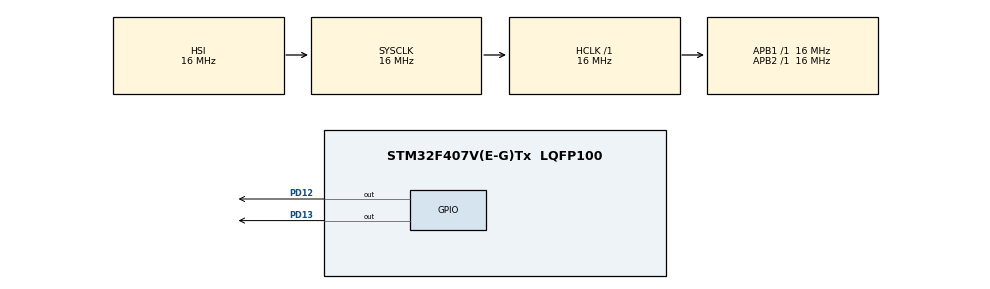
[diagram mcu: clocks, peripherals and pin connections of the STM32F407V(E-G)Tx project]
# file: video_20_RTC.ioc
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Mcu.Family=STM32F4
Mcu.Name=STM32F407V(E-G)Tx
Mcu.Package=LQFP100
NVIC.PriorityGroup=NVIC_PRIORITYGROUP_4
NVIC.RTC_Alarm_IRQn=true\:0\:0\:false\:false\:true\:true
PA13.Mode=Serial_Wire
PA13.Signal=SYS_JTMS-SWDIO
PA14.Mode=Serial_Wire
PA14.Signal=SYS_JTCK-SWCLK
PD12.Signal=GPIO_Output
PD13.Signal=GPIO_Output
ProjectManager.HeapSize=0x200
ProjectManager.StackSize=0x400
ProjectManager.TargetToolchain=MDK-ARM V5
RCC.AHBFreq_Value=16000000
RCC.APB1Freq_Value=16000000
RCC.APB1TimFreq_Value=16000000
RCC.APB2Freq_Value=16000000
RCC.APB2TimFreq_Value=16000000
RCC.CortexFreq_Value=16000000
RCC.HCLKFreq_Value=16000000
RCC.HSE_VALUE=25000000
RCC.HSI_VALUE=16000000
RCC.SYSCLKFreq_VALUE=16000000
RCC.VCOOutputFreq_Value=192000000
RTC.Alarm=RTC_ALARM_A
RTC.AlarmDateWeekDaySel=RTC_ALARMDATEWEEKDAYSEL_DATE
RTC.Date=31
RTC.Format=RTC_FORMAT_BIN
RTC.Hours=23
RTC.Minutes=59
RTC.Month=RTC_MONTH_DECEMBER
RTC.Seconds=45
RTC.Seconds_A=10
RTC.Year=18
VP_RTC_VS_RTC_Activate.Mode=RTC_Enabled
VP_RTC_VS_RTC_Alarm_A_Intern.Mode=Alarm A
VP_RTC_VS_RTC_Calendar.Mode=RTC_Calendar
board=video_20_RTC

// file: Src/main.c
/**
  ******************************************************************************
  * File Name          : main.c
  * Description        : Main program body
  ******************************************************************************
  ** This notice applies to any and all portions of this file
  * that are not between comment pairs USER CODE BEGIN and
  * USER CODE END. Other portions of this file, whether
  * inserted by the user or by software development tools
  * are owned by their respective copyright owners.
  *
  * COPYRIGHT(c) 2018 STMicroelectronics
  *
  * Redistribution and use in source and binary forms, with or without modification,
  * are permitted provided that the following conditions are met:
  *   1. Redistributions of source code must retain the above copyright notice,
  *      this list of conditions and the following disclaimer.
  *   2. Redistributions in binary form must reproduce the above copyright notice,
  *      this list of conditions and the following disclaimer in the documentation
  *      and/or other materials provided with the distribution.
  *   3. Neither the name of STMicroelectronics nor the names of its contributors
  *      may be used to endorse or promote products derived from this software
  *      without specific prior written permission.
  *
  * THIS SOFTWARE IS PROVIDED BY THE COPYRIGHT HOLDERS AND CONTRIBUTORS "AS IS"
  * AND ANY EXPRESS OR IMPLIED WARRANTIES, INCLUDING, BUT NOT LIMITED TO, THE
  * IMPLIED WARRANTIES OF MERCHANTABILITY AND FITNESS FOR A PARTICULAR PURPOSE ARE
  * DISCLAIMED. IN NO EVENT SHALL THE COPYRIGHT HOLDER OR CONTRIBUTORS BE LIABLE
  * FOR ANY DIRECT, INDIRECT, INCIDENTAL, SPECIAL, EXEMPLARY, OR CONSEQUENTIAL
  * DAMAGES (INCLUDING, BUT NOT LIMITED TO, PROCUREMENT OF SUBSTITUTE GOODS OR
  * SERVICES; LOSS OF USE, DATA, OR PROFITS; OR BUSINESS INTERRUPTION) HOWEVER
  * CAUSED AND ON ANY THEORY OF LIABILITY, WHETHER IN CONTRACT, STRICT LIABILITY,
  * OR TORT (INCLUDING NEGLIGENCE OR OTHERWISE) ARISING IN ANY WAY OUT OF THE USE
  * OF THIS SOFTWARE, EVEN IF ADVISED OF THE POSSIBILITY OF SUCH DAMAGE.
  *
  ******************************************************************************
  */
#include "main.h"
#include "stm32f4xx_hal.h"

RTC_HandleTypeDef hrtc;
RTC_TimeTypeDef  sTime;             //<== tanimlama kismi
RTC_DateTypeDef  sDate;

/* USER CODE BEGIN PV */
/* Private variables ---------------------------------------------------------*/

/* USER CODE END PV */

void SystemClock_Config(void);
static void MX_GPIO_Init(void);
static void MX_RTC_Init(void);

/* USER CODE BEGIN PFP */
/* Private function prototypes -----------------------------------------------*/

/* USER CODE END PFP */

int main(void)
{

  /* MCU Configuration----------------------------------------------------------*/

  /* Reset of all peripherals, Initializes the Flash interface and the Systick. */
  HAL_Init();

  /* Configure the system clock */
  SystemClock_Config();

  /* Initialize all configured peripherals */
  MX_GPIO_Init();
  MX_RTC_Init();

//  videoda adamin yaptigi ama bnm yapmama gerek olmayan kisim :
// ilk yaptigimda bunlara gerek yoktu ama sonradan bu kodlari uncomment yapmak zorunda kaldim
// asagida fonksiyonda var ama bastan yükleyince degismedi dene acaba????
  /* USER CODE BEGIN 2 */
	// --------------------------------------------------------
//  // 1) Set time:
//    sTime.Hours = 23;
//    sTime.Minutes = 59;
//    sTime.Seconds = 45;
//	HAL_RTC_SetTime(&hrtc, &sTime, RTC_FORMAT_BIN);
//  // Sknti su nasil o fonksiyonun içinde deger atayacagim ??????????????
////	 ------------------------------------------------------------
//	// 2) Set date:
//	sDate.WeekDay = RTC_WEEKDAY_SUNDAY;
//  sDate.Month = RTC_MONTH_DECEMBER;
//  sDate.Date = 31;
//	sDate.Year = 18;
//	HAL_RTC_SetDate(&hrtc, &sDate, RTC_FORMAT_BIN);
//// ------------------------------------------------------------------ uncomment yaptigim yerin sonu
//  STM YI ÇIKARTIP SONRA PROGRAMI YÜKLEYINCE ÇALISIYOR  :|
  /* USER CODE END 2 */

  /* Infinite loop */
  while (1)
  {
	 HAL_RTC_GetTime(&hrtc,&sTime,RTC_FORMAT_BIN);
	 HAL_RTC_GetDate(&hrtc,&sDate,RTC_FORMAT_BIN);
   HAL_GPIO_TogglePin(GPIOD,GPIO_PIN_13);
   HAL_Delay(200);
  }

}

/** System Clock Configuration
*/
void SystemClock_Config(void)
{

  RCC_OscInitTypeDef RCC_OscInitStruct;
  RCC_ClkInitTypeDef RCC_ClkInitStruct;
  RCC_PeriphCLKInitTypeDef PeriphClkInitStruct;

    /**Configure the main internal regulator output voltage
    */
  __HAL_RCC_PWR_CLK_ENABLE();

  __HAL_PWR_VOLTAGESCALING_CONFIG(PWR_REGULATOR_VOLTAGE_SCALE1);

    /**Initializes the CPU, AHB and APB busses clocks
    */
  RCC_OscInitStruct.OscillatorType = RCC_OSCILLATORTYPE_HSI|RCC_OSCILLATORTYPE_LSI;
  RCC_OscInitStruct.HSIState = RCC_HSI_ON;
  RCC_OscInitStruct.HSICalibrationValue = 16;
  RCC_OscInitStruct.LSIState = RCC_LSI_ON;
  RCC_OscInitStruct.PLL.PLLState = RCC_PLL_NONE;
  if (HAL_RCC_OscConfig(&RCC_OscInitStruct) != HAL_OK)
  {
    _Error_Handler(__FILE__, __LINE__);
  }

    /**Initializes the CPU, AHB and APB busses clocks
    */
  RCC_ClkInitStruct.ClockType = RCC_CLOCKTYPE_HCLK|RCC_CLOCKTYPE_SYSCLK
                              |RCC_CLOCKTYPE_PCLK1|RCC_CLOCKTYPE_PCLK2;
  RCC_ClkInitStruct.SYSCLKSource = RCC_SYSCLKSOURCE_HSI;
  RCC_ClkInitStruct.AHBCLKDivider = RCC_SYSCLK_DIV1;
  RCC_ClkInitStruct.APB1CLKDivider = RCC_HCLK_DIV1;
  RCC_ClkInitStruct.APB2CLKDivider = RCC_HCLK_DIV1;

  if (HAL_RCC_ClockConfig(&RCC_ClkInitStruct, FLASH_LATENCY_0) != HAL_OK)
  {
    _Error_Handler(__FILE__, __LINE__);
  }

  PeriphClkInitStruct.PeriphClockSelection = RCC_PERIPHCLK_RTC;
  PeriphClkInitStruct.RTCClockSelection = RCC_RTCCLKSOURCE_LSI;
  if (HAL_RCCEx_PeriphCLKConfig(&PeriphClkInitStruct) != HAL_OK)
  {
    _Error_Handler(__FILE__, __LINE__);
  }

    /**Configure the Systick interrupt time
    */
  HAL_SYSTICK_Config(HAL_RCC_GetHCLKFreq()/1000);

    /**Configure the Systick
    */
  HAL_SYSTICK_CLKSourceConfig(SYSTICK_CLKSOURCE_HCLK);

  /* SysTick_IRQn interrupt configuration */
  HAL_NVIC_SetPriority(SysTick_IRQn, 0, 0);
}

/* RTC init function */
static void MX_RTC_Init(void)
{

  RTC_TimeTypeDef sTime;
  RTC_DateTypeDef sDate;
  RTC_AlarmTypeDef sAlarm;

    /**Initialize RTC Only
    */
  hrtc.Instance = RTC;
  hrtc.Init.HourFormat = RTC_HOURFORMAT_24;
  hrtc.Init.AsynchPrediv = 127;
  hrtc.Init.SynchPrediv = 255;
  hrtc.Init.OutPut = RTC_OUTPUT_DISABLE;
  hrtc.Init.OutPutPolarity = RTC_OUTPUT_POLARITY_HIGH;
  hrtc.Init.OutPutType = RTC_OUTPUT_TYPE_OPENDRAIN;
  if (HAL_RTC_Init(&hrtc) != HAL_OK)
  {
    _Error_Handler(__FILE__, __LINE__);
  }

    /**Initialize RTC and set the Time and Date
    */
  if(HAL_RTCEx_BKUPRead(&hrtc, RTC_BKP_DR0) != 0x32F2){
  sTime.Hours = 23;
  sTime.Minutes = 59;
  sTime.Seconds = 45;
  sTime.DayLightSaving = RTC_DAYLIGHTSAVING_NONE;
  sTime.StoreOperation = RTC_STOREOPERATION_RESET;
  if (HAL_RTC_SetTime(&hrtc, &sTime, RTC_FORMAT_BIN) != HAL_OK)
  {
    _Error_Handler(__FILE__, __LINE__);
  }

  sDate.WeekDay = RTC_WEEKDAY_SUNDAY;
  sDate.Month = RTC_MONTH_DECEMBER;
  sDate.Date = 31;
  sDate.Year = 17;

  if (HAL_RTC_SetDate(&hrtc, &sDate, RTC_FORMAT_BIN) != HAL_OK)
  {
    _Error_Handler(__FILE__, __LINE__);
  }

    HAL_RTCEx_BKUPWrite(&hrtc,RTC_BKP_DR0,0x32F2);
  }
    /**Enable the Alarm A
    */
  sAlarm.AlarmTime.Hours = 0;
  sAlarm.AlarmTime.Minutes = 0;
  sAlarm.AlarmTime.Seconds = 10;
  sAlarm.AlarmTime.SubSeconds = 0;
  sAlarm.AlarmTime.DayLightSaving = RTC_DAYLIGHTSAVING_NONE;
  sAlarm.AlarmTime.StoreOperation = RTC_STOREOPERATION_RESET;
  sAlarm.AlarmMask = RTC_ALARMMASK_NONE;
  sAlarm.AlarmSubSecondMask = RTC_ALARMSUBSECONDMASK_ALL;
  sAlarm.AlarmDateWeekDaySel = RTC_ALARMDATEWEEKDAYSEL_DATE;
  sAlarm.AlarmDateWeekDay = 1;
  sAlarm.Alarm = RTC_ALARM_A;
  if (HAL_RTC_SetAlarm_IT(&hrtc, &sAlarm, RTC_FORMAT_BIN) != HAL_OK)
  {
    _Error_Handler(__FILE__, __LINE__);
  }

}

/** Configure pins as
        * Analog
        * Input
        * Output
        * EVENT_OUT
        * EXTI
*/
static void MX_GPIO_Init(void)
{

  GPIO_InitTypeDef GPIO_InitStruct;

  /* GPIO Ports Clock Enable */
  __HAL_RCC_GPIOD_CLK_ENABLE();
  __HAL_RCC_GPIOA_CLK_ENABLE();

  /*Configure GPIO pin Output Level */
  HAL_GPIO_WritePin(GPIOD, GPIO_PIN_12|GPIO_PIN_13, GPIO_PIN_RESET);

  /*Configure GPIO pins : PD12 PD13 */
  GPIO_InitStruct.Pin = GPIO_PIN_12|GPIO_PIN_13;
  GPIO_InitStruct.Mode = GPIO_MODE_OUTPUT_PP;
  GPIO_InitStruct.Pull = GPIO_NOPULL;
  GPIO_InitStruct.Speed = GPIO_SPEED_FREQ_LOW;
  HAL_GPIO_Init(GPIOD, &GPIO_InitStruct);

}

/* USER CODE BEGIN 4 */
void HAL_RTC_AlarmAEventCallback(RTC_HandleTypeDef *hrtc)
{
  /* Prevent unused argument(s) compilation warning */
  UNUSED(hrtc);
  /* NOTE : This function Should not be modified, when the callback is needed,
            the HAL_RTC_AlarmAEventCallback could be implemented in the user file
   */
	HAL_GPIO_TogglePin(GPIOD,GPIO_PIN_12);
}
/* USER CODE END 4 */

void _Error_Handler(char * file, int line)
{
  while(1)
  {
  }
}

/************************ (C) COPYRIGHT STMicroelectronics *****END OF FILE****/
